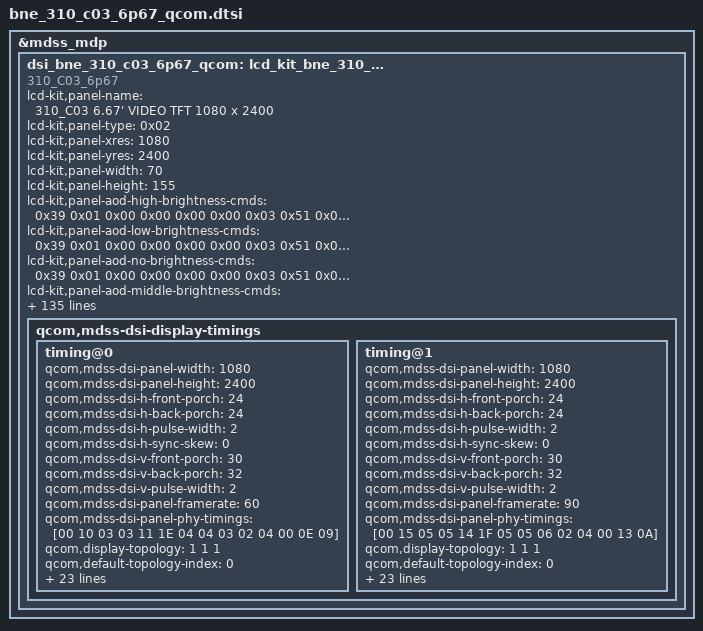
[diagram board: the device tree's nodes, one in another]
/* Copyright (c) 2013, The Linux Foundation. All rights reserved.
 *
 * This program is free software; you can redistribute it and/or modify
 * it under the terms of the GNU General Public License version 2 and
 * only version 2 as published by the Free Software Foundation.
 *
 * This program is distributed in the hope that it will be useful,
 * but WITHOUT ANY WARRANTY; without even the implied warranty of
 * MERCHANTABILITY or FITNESS FOR A PARTICULAR PURPOSE.  See the
 * GNU General Public License for more details.
 */

/*-------------------------------------------------------------------------
 * This file is autogenerated file using gcdb parser. Please do not edit it.
 * Update input XML file to add a new entry or update variable in this file
 * VERSION = 1.1
 *-----------------------------------------------------------------------*/
&mdss_mdp {
	dsi_bne_310_c03_6p67_qcom: lcd_kit_bne_310_c03_6p67_qcom {
		compatible = "310_C03_6p67";
		lcd-kit,panel-name = "310_C03 6.67' VIDEO TFT 1080 x 2400";
		lcd-kit,panel-type = <0x02>;
		lcd-kit,panel-xres = <1080>;
		lcd-kit,panel-yres = <2400>;
		lcd-kit,panel-width = <70>;
		lcd-kit,panel-height = <155>;
		lcd-kit,panel-aod-high-brightness-cmds = <0x39 0x01 0x00 0x00 0x00 0x00 0x03 0x51 0x0F 0xFF
		0x15 0x01 0x00 0x00 0x00 0x00 0x02 0xFE 0x00>;
		lcd-kit,panel-aod-low-brightness-cmds = <0x39 0x01 0x00 0x00 0x00 0x00 0x03 0x51 0x08 0x88
		0x15 0x01 0x00 0x00 0x00 0x00 0x02 0xFE 0x00>;
		lcd-kit,panel-aod-no-brightness-cmds = <0x39 0x01 0x00 0x00 0x00 0x00 0x03 0x51 0x00 0x00
		0x15 0x01 0x00 0x00 0x00 0x00 0x02 0xFE 0x00>;
		lcd-kit,panel-aod-middle-brightness-cmds = <0x39 0x01 0x00 0x00 0x00 0x00 0x03 0x51 0x0B 0xFF
		0x15 0x01 0x00 0x00 0x00 0x00 0x02 0xFE 0x00>;
		lcd-kit,hor-line-cmds = <0x15 0x01 0x00 0x00 0x0a 0x00 0x02 0xFE 0x84
		0x15 0x01 0x00 0x00 0x0a 0x00 0x02 0xE0 0x80
		0x15 0x01 0x00 0x00 0x0a 0x00 0x02 0xFE 0x40
		0x15 0x01 0x00 0x00 0x0a 0x00 0x02 0x74 0x4E
		0x15 0x01 0x00 0x00 0x0a 0x00 0x02 0x24 0x5F
		0x15 0x01 0x00 0x00 0x0a 0x00 0x02 0x26 0x5F
		0x15 0x01 0x00 0x00 0x0a 0x00 0x02 0x28 0x5F
		0x15 0x01 0x00 0x00 0x0a 0x00 0x02 0x2A 0x5F
		0x15 0x01 0x00 0x00 0x0a 0x00 0x02 0x2D 0x46
		0x15 0x01 0x00 0x00 0x0a 0x00 0x02 0x2F 0x46
		0x15 0x01 0x00 0x00 0x0a 0x00 0x02 0x36 0xC0
		0x15 0x01 0x00 0x00 0x0a 0x00 0x02 0x37 0x68
		0x15 0x01 0x00 0x00 0x0a 0x00 0x02 0x38 0x68
		0x15 0x01 0x00 0x00 0x00 0x00 0x02 0xFE 0x00>;
		lcd-kit,hor-line-cmds-state = "dsi_lp_mode";
		lcd-kit,vtc-line-cmds = <0x15 0x01 0x00 0x00 0x0a 0x00 0x02 0xFE 0x90
		0x15 0x01 0x00 0x00 0x0a 0x00 0x02 0x12 0xB7
		0x15 0x01 0x00 0x00 0x0a 0x00 0x02 0xFE 0x40
		0x15 0x01 0x00 0x00 0x0a 0x00 0x02 0x66 0xA0
		0x15 0x01 0x00 0x00 0x0a 0x00 0x02 0x67 0xC3
		0x15 0x01 0x00 0x00 0x0a 0x00 0x02 0xFE 0xA0
		0x15 0x01 0x00 0x00 0x0a 0x00 0x02 0x04 0x07
		0x15 0x01 0x00 0x00 0x0a 0x00 0x02 0x31 0x10
		0x15 0x01 0x00 0x00 0x0a 0x00 0x02 0x32 0x10
		0x15 0x01 0x00 0x00 0x0a 0x00 0x02 0xFE 0x40
		0x15 0x01 0x00 0x00 0x0a 0x00 0x02 0x74 0x4E
		0x15 0x01 0x00 0x00 0x0a 0x00 0x02 0xFE 0x70
		0x15 0x01 0x00 0x00 0x0a 0x00 0x02 0x71 0x00
		0x15 0x01 0x00 0x00 0x0a 0x00 0x02 0x72 0x31
		0x15 0x01 0x00 0x00 0x0a 0x00 0x02 0xFE 0x50
		0x15 0x01 0x00 0x00 0x0a 0x00 0x02 0x00 0xB9
		0x15 0x01 0x00 0x00 0x0a 0x00 0x02 0x01 0xB0
		0x15 0x01 0x00 0x00 0x0a 0x00 0x02 0x02 0x6F
		0x15 0x01 0x00 0x00 0x0a 0x00 0x02 0x03 0x90
		0x15 0x01 0x00 0x00 0x0a 0x00 0x02 0x04 0xEE
		0x15 0x01 0x00 0x00 0x00 0x00 0x02 0xFE 0x00>;
		lcd-kit,vtc-line-cmds-state  = "dsi_lp_mode";
		lcd-kit,bl-after-frame = <0>;
		lcd-kit,ap-aod-support = <1>;
		lcd-kit,dc-delay-support = <1>;
		lcd-kit,dc-left-time-to-te-us = <6800>;
		lcd-kit,dc-right-time-to-te-us = <7600>;
		lcd-kit,dc-delay-time-before-fp = <16667>;
		lcd-kit,dc-delay-time-after-fp = <16667>;
		lcd-kit,vtc-line-support = <0>;
		lcd-kit,hor-line-support = <0>;
		lcd-kit,hor-line-duration = <600>;
		lcd-kit,vtc-line-no-reset = <0>;
		qcom,mdss-dsi-panel-type = "dsi_cmd_mode";
		qcom,mdss-dsi-panel-name = "310_C03_6p67";
		qcom,mdss-pan-physical-width-dimension = <70>;
		qcom,mdss-pan-physical-height-dimension = <155>;
		qcom,dsi-ctrl-num = <0>;
		qcom,dsi-phy-num = <0>;
		qcom,panel-supply-entries = <&dsi_panel_pwr_supply>;
		qcom,mdss-dsi-virtual-channel-id = <0>;
		qcom,mdss-dsi-h-sync-pulse = <0>;
		qcom,mdss-dsi-bllp-eof-power-mode;
		qcom,mdss-dsi-bllp-power-mode;
		qcom,mdss-dsi-dma-schedule-line = <1>;
		qcom,mdss-dsi-bpp = <24>;
		qcom,mdss-dsi-color-order = "rgb_swap_rgb";
		qcom,mdss-dsi-underflow-color = <0xff>;
		qcom,mdss-dsi-border-color = <0>;
		qcom,mdss-dsi-traffic-mode = "burst_mode";
		qcom,mdss-dsi-lane-map = "lane_map_0123";
		qcom,mdss-dsi-lane-0-state;
		qcom,mdss-dsi-lane-1-state;
		qcom,mdss-dsi-lane-2-state;
		qcom,mdss-dsi-lane-3-state;
		qcom,mdss-dsi-mdp-trigger = "none";
		qcom,mdss-dsi-dma-trigger = "trigger_sw";
		qcom,mdss-dsi-te-pin-select = <1>;
		qcom,mdss-dsi-wr-mem-start = <0x2c>;
		qcom,mdss-dsi-wr-mem-continue = <0x3c>;
		qcom,mdss-dsi-te-dcs-command = <1>;
		qcom,mdss-dsi-te-check-enable;
		qcom,mdss-dsi-te-using-te-pin;
		qcom,dsi-panel-gpio-address = <0x0F100000 0x1000>;
		qcom,dsi-panel-gpio-pins = <12 82 81>;
		qcom,dsi-panel-gpio-names = "reg-gpio", "reset-gpio", "platform-te-gpio";
		qcom,mdss-dsi-t-clk-post = <0x09>;
		qcom,mdss-dsi-t-clk-pre = <0x0E>;
		qcom,mdss-dsi-tx-eot-append;
		qcom,dsi-select-clocks = "mux_byte_clk0", "mux_pixel_clk0", "src_byte_clk0", "src_pixel_clk0", "shadow_byte_clk0", "shadow_pixel_clk0";
		qcom,mdss-dsi-stream = <0>;
		qcom,mdss-dsi-lp11-init;
		qcom,sublinks-count = <2>;
		qcom,lanes-per-sublink = <2>;
		qcom,mdss-dsi-panel-hdr-color-primaries = <14500 15500 32000 17000 15500 30000 8000 3000>;
		qcom,mdss-dsi-panel-peak-brightness = <4200000>;
		qcom,mdss-dsi-panel-blackness-level = <3230>;
		qcom,dynamic-mode-switch-enabled;
		qcom,dynamic-mode-switch-type = "dynamic-resolution-switch-immediate";
		qcom,mdss-dsi-bl-pmic-control-type = "bl_ctrl_dcs";
		pwms = <&pm6125_pwm 0 0>;
		qcom,bl-pmic-pwm-period-usecs = <100>;
		qcom,mdss-dsi-bl-min-level = <1>;
		qcom,mdss-dsi-bl-max-level = <10000>;
		qcom,esd-check-enabled;
		qcom,mdss-dsi-panel-status-command = [15 01 00 00 00 00 02 FE 00
			06 01 00 00 00 00 01 0A
			15 01 00 00 00 00 02 FE D0
			15 01 00 00 11 00 02 B9 02
			15 01 00 00 00 00 02 B9 00
			15 01 00 00 11 00 02 FE 00
			15 01 00 00 00 00 02 FE 00
			06 01 00 00 00 00 01 FE];
		qcom,mdss-dsi-panel-status-command-state = "dsi_lp_mode";
		qcom,mdss-dsi-panel-status-check-mode = "reg_read";
		qcom,mdss-dsi-panel-status-read-length = <0 1 0 0 0 0 0 1>;
		qcom,mdss-dsi-panel-status-value = <0x9C>,<0x00>;
		lcd-kit,power-on-stage = <2 1 2
				9 1 1
				1 1 12
				5 1 5
				5 0 1
				5 1 15
				7 1 0
				6 1 0
				8 1 0>;
		lcd-kit,lp-on-stage = <0 0 0>;
		lcd-kit,lp-off-stage = <0 0 0>;
		lcd-kit,power-off-stage = <7 0 0
				6 0 0
				8 0 0
				5 0 1
				1 0 3
				9 0 2
				2 0 1>;
		lcd-kit,only-power-off-stage = <0 0 0>;
		lcd-kit,pt-support = <1>;
		lcd-kit,panel-on-always-reset = <0>;
		lcd-kit,lcd-vci = <2 27 3000000 3000000 3000000 10000 80>;
		lcd-kit,lcd-iovcc = <2 26 1800000 1800000 1800000 60700 80>;
		lcd-kit,lcd-vdd = <2 65 1200000 1200000 1200000 30000 80>;
		lcd-kit,lcd-reset = <2 82 0>;
		lcd-kit,lcd-vci-name = "vdd";
		lcd-kit,lcd-iovcc-name = "vddio";
		lcd-kit,lcd-vdd-name = "ddic";
		lcd-kit,project-id-support = <0>;
		lcd-kit,default-project-id = "G240A7130";
		lcd-kit,sn-code-support = <1>;
		lcd-kit,oem-info-support = <1>;
		lcd-kit,oem-barcode-2d-support = <1>;
		lcd-kit,oem-barcode-2d-num-offset = <0>;
		lcd-kit,barcode-2d-cmds = <0x15 0x01 0x00 0x00 0x00 0x00 0x02 0xFE 0xC2
		0x06 0x01 0x00 0x00 0x00 0x00 0x01 0x01
		0x06 0x01 0x00 0x00 0x00 0x00 0x01 0x02
		0x06 0x01 0x00 0x00 0x00 0x00 0x01 0x03
		0x06 0x01 0x00 0x00 0x00 0x00 0x01 0x04
		0x06 0x01 0x00 0x00 0x00 0x00 0x01 0x05
		0x06 0x01 0x00 0x00 0x00 0x00 0x01 0x06
		0x06 0x01 0x00 0x00 0x00 0x00 0x01 0x07
		0x06 0x01 0x00 0x00 0x00 0x00 0x01 0x08
		0x06 0x01 0x00 0x00 0x00 0x00 0x01 0x09
		0x06 0x01 0x00 0x00 0x00 0x00 0x01 0x0A
		0x06 0x01 0x00 0x00 0x00 0x00 0x01 0x0B
		0x06 0x01 0x00 0x00 0x00 0x00 0x01 0x0C
		0x06 0x01 0x00 0x00 0x00 0x00 0x01 0x0D
		0x06 0x01 0x00 0x00 0x00 0x00 0x01 0x0E
		0x06 0x01 0x00 0x00 0x00 0x00 0x01 0x0F
		0x06 0x01 0x00 0x00 0x00 0x00 0x01 0x10
		0x06 0x01 0x00 0x00 0x00 0x00 0x01 0x11
		0x06 0x01 0x00 0x00 0x00 0x00 0x01 0x12
		0x06 0x01 0x00 0x00 0x00 0x00 0x01 0x13
		0x06 0x01 0x00 0x00 0x00 0x00 0x01 0x14
		0x06 0x01 0x00 0x00 0x00 0x00 0x01 0x15
		0x15 0x01 0x00 0x00 0x00 0x00 0x02 0xFE 0x00>;
		lcd-kit,barcode-2d-cmds-state = "dsi_lp_mode";
		lcd-kit,panel-getblmaxnit-type = <0>;
		lcd-kit,panel-blmaxnit-min-value = <400>;
		lcd-kit,inversion-support = <0>;
		lcd-kit,panel-gpio-offset = <1167>;
		lcd-kit,panel-bl-max-nit = <450>;
		lcd-kit,panel-bl-min = <1>;
		lcd-kit,panel-bl-max = <10000>;
		lcd-kit,panel-bl-def = <2047>;
		lcd-kit,check-reg-support = <0>;
		lcd-kit,thp-proximity-support = <0>;
		lcd-kit,proximity-reset-delay-min = <65>;
		lcd-kit,backlight-cmds = <0x39 0x01 0x00 0x00 0x00 0x00 0x03 0x51 0x00 0x00>;
		lcd-kit,backlight-cmds-state = "dsi_lp_mode";
		lcd-kit,backlight-order = <0>;
		lcd-kit,quickly-sleep-out-support = <0>;
		lcd-kit,quickly-sleep-out-interval = <0>;
		lcd-kit,fps-support = <1>;
		lcd-kit,default-fps = <60>;
		lcd-kit,panel-support-fps-list = <60 90>;
		qcom,mdss-dsi-display-timings {
			timing@0 {
				qcom,mdss-dsi-panel-width = <1080>;
				qcom,mdss-dsi-panel-height = <2400>;
				qcom,mdss-dsi-h-front-porch = <24>;
				qcom,mdss-dsi-h-back-porch = <24>;
				qcom,mdss-dsi-h-pulse-width = <2>;
				qcom,mdss-dsi-h-sync-skew = <0>;
				qcom,mdss-dsi-v-front-porch = <30>;
				qcom,mdss-dsi-v-back-porch = <32>;
				qcom,mdss-dsi-v-pulse-width = <2>;
				qcom,mdss-dsi-panel-framerate = <60>;
				qcom,mdss-dsi-panel-phy-timings= [00 10 03 03 11 1E 04
			04 03 02 04 00 0E 09];
				qcom,display-topology  = <1 1 1>;
				qcom,default-topology-index  = <0>;
				qcom,mdss-dsi-on-command = [15 01 00 00 00 00 02 FE D0
		15 01 00 00 00 00 02 2A 80
		15 01 00 00 00 00 02 FE D2
		15 01 00 00 00 00 02 53 08
		15 01 00 00 00 00 02 00 11
		15 01 00 00 00 00 02 01 AB
		15 01 00 00 00 00 02 02 30
		15 01 00 00 00 00 02 03 09
		15 01 00 00 00 00 02 04 60
		15 01 00 00 00 00 02 05 04
		15 01 00 00 00 00 02 06 38
		15 01 00 00 00 00 02 07 00
		15 01 00 00 00 00 02 08 0C
		15 01 00 00 00 00 02 09 04
		15 01 00 00 00 00 02 0A 38
		15 01 00 00 00 00 02 0B 02
		15 01 00 00 00 00 02 0C 00
		15 01 00 00 00 00 02 0D 20
		15 01 00 00 00 00 02 0E 01
		15 01 00 00 00 00 02 0F 47
		15 01 00 00 00 00 02 10 00
		15 01 00 00 00 00 02 11 0F
		15 01 00 00 00 00 02 12 0F
		15 01 00 00 00 00 02 13 0A
		15 01 00 00 00 00 02 14 E9
		15 01 00 00 00 00 02 15 04
		15 01 00 00 00 00 02 16 3D
		15 01 00 00 00 00 02 17 18
		15 01 00 00 00 00 02 18 00
		15 01 00 00 00 00 02 19 10
		15 01 00 00 00 00 02 1A F0
		15 01 00 00 00 00 02 1B 07
		15 01 00 00 00 00 02 1C 10
		15 01 00 00 00 00 02 1D 20
		15 01 00 00 00 00 02 1E 00
		15 01 00 00 00 00 02 1F 06
		15 01 00 00 00 00 02 20 0F
		15 01 00 00 00 00 02 21 0F
		15 01 00 00 00 00 02 22 33
		15 01 00 00 00 00 02 23 0E
		15 01 00 00 00 00 02 24 1C
		15 01 00 00 00 00 02 25 2A
		15 01 00 00 00 00 02 26 38
		15 01 00 00 00 00 02 27 46
		15 01 00 00 00 00 02 28 54
		15 01 00 00 00 00 02 29 62
		15 01 00 00 00 00 02 2A 69
		15 01 00 00 00 00 02 2B 70
		15 01 00 00 00 00 02 2D 77
		15 01 00 00 00 00 02 2F 79
		15 01 00 00 00 00 02 30 7B
		15 01 00 00 00 00 02 31 7D
		15 01 00 00 00 00 02 32 7E
		15 01 00 00 00 00 02 33 02
		15 01 00 00 00 00 02 34 02
		15 01 00 00 00 00 02 35 22
		15 01 00 00 00 00 02 36 00
		15 01 00 00 00 00 02 37 2A
		15 01 00 00 00 00 02 38 40
		15 01 00 00 00 00 02 39 2A
		15 01 00 00 00 00 02 3A BE
		15 01 00 00 00 00 02 3B 3A
		15 01 00 00 00 00 02 3D FC
		15 01 00 00 00 00 02 3F 3A
		15 01 00 00 00 00 02 40 FA
		15 01 00 00 00 00 02 41 3A
		15 01 00 00 00 00 02 42 F8
		15 01 00 00 00 00 02 43 3B
		15 01 00 00 00 00 02 44 38
		15 01 00 00 00 00 02 45 3B
		15 01 00 00 00 00 02 46 78
		15 01 00 00 00 00 02 47 3B
		15 01 00 00 00 00 02 48 B6
		15 01 00 00 00 00 02 49 4B
		15 01 00 00 00 00 02 4A B6
		15 01 00 00 00 00 02 4B 4B
		15 01 00 00 00 00 02 4C F4
		15 01 00 00 00 00 02 4D 4B
		15 01 00 00 00 00 02 4E F4
		15 01 00 00 00 00 02 4F 6C
		15 01 00 00 00 00 02 50 34
		15 01 00 00 00 00 02 51 84
		15 01 00 00 00 00 02 52 74
		15 01 00 00 00 00 02 86 04
		15 01 00 00 00 00 02 87 38
		15 01 00 00 00 00 02 88 00
		15 01 00 00 00 00 02 89 00
		15 01 00 00 00 00 02 8A 00
		15 01 00 00 00 00 02 8B 00
		15 01 00 00 00 00 02 8C 00
		15 01 00 00 00 00 02 8D 00
		15 01 00 00 00 00 02 8E 80
		15 01 00 00 00 00 02 FE A0
		15 01 00 00 00 00 02 28 1B
		15 01 00 00 00 00 02 FE 40
		15 01 00 00 00 00 02 2F 25
		15 01 00 00 00 00 02 47 2F
		15 01 00 00 00 00 02 FE 70
		15 01 00 00 00 00 02 19 2E
		15 01 00 00 00 00 02 FE 84
		15 01 00 00 00 00 02 E0 90
		15 01 00 00 00 00 02 D9 80
		15 01 00 00 00 00 02 E1 BC
		15 01 00 00 00 00 02 E7 04
		15 01 00 00 00 00 02 E8 D0
		15 01 00 00 00 00 02 FE D0
		15 01 00 00 00 00 02 9C 84
		15 01 00 00 00 00 02 48 D0
		15 01 00 00 00 00 02 FE 78
		15 01 00 00 00 00 02 A0 01
		15 01 00 00 00 00 02 A2 01
		15 01 00 00 00 00 02 A3 02
		15 01 00 00 00 00 02 A4 04
		15 01 00 00 00 00 02 A5 05
		15 01 00 00 00 00 02 A6 06
		15 01 00 00 00 00 02 A7 07
		15 01 00 00 00 00 02 A9 08
		15 01 00 00 00 00 02 AA 09
		15 01 00 00 00 00 02 AB 09
		15 01 00 00 00 00 02 AC 0A
		15 01 00 00 00 00 02 FE 84
		15 01 00 00 00 00 02 59 0B
		15 01 00 00 00 00 02 5A 0B
		15 01 00 00 00 00 02 5B 0C
		15 01 00 00 00 00 02 5C 0E
		15 01 00 00 00 00 02 5D 0F
		15 01 00 00 00 00 02 5E 10
		15 01 00 00 00 00 02 5F 11
		15 01 00 00 00 00 02 60 12
		15 01 00 00 00 00 02 61 13
		15 01 00 00 00 00 02 62 13
		15 01 00 00 00 00 02 63 14
		15 01 00 00 00 00 02 FE 82
		15 01 00 00 00 00 02 00 01
		15 01 00 00 00 00 02 02 D0
		15 01 00 00 00 00 02 03 0A
		15 01 00 00 00 00 02 05 F0
		15 01 00 00 00 00 02 A4 DD
		15 01 00 00 00 00 02 A5 DD
		15 01 00 00 00 00 02 A6 DD
		15 01 00 00 00 00 02 A7 DD
		15 01 00 00 00 00 02 A9 DD
		15 01 00 00 00 00 02 AA DD
		15 01 00 00 00 00 02 AB DD
		15 01 00 00 00 00 02 AC DD
		15 01 00 00 00 00 02 AD FF
		15 01 00 00 00 00 02 AE FF
		15 01 00 00 00 00 02 AF FF
		15 01 00 00 00 00 02 B0 FF
		15 01 00 00 00 00 02 8B FF
		15 01 00 00 00 00 02 8C FF
		15 01 00 00 00 00 02 9A FF
		15 01 00 00 00 00 02 9B FF
		15 01 00 00 00 00 02 FE A0
		15 01 00 00 00 00 02 1F 1E
		15 01 00 00 00 00 02 30 37
		15 01 00 00 00 00 02 FE D0
		15 01 00 00 00 00 02 42 81
		15 01 00 00 00 00 02 FE 00
		15 01 00 00 00 00 02 FA 01
		15 01 00 00 00 00 02 5E 01
		15 01 00 00 00 00 02 C2 08
		15 01 00 00 00 00 02 35 00
		05 01 00 00 78 00 01 11
		05 01 00 00 14 00 01 29
		15 01 00 00 00 00 02 FE 00];
				qcom,mdss-dsi-on-command-state = "dsi_lp_mode";
				qcom,mdss-dsi-off-command = [05 01 00 00 14 00 01 28
		05 01 00 00 78 00 01 10
		15 01 00 00 00 00 02 FE 00];
				qcom,mdss-dsi-off-command-state = "dsi_lp_mode";
				qcom,compression-mode = "dsc";
				qcom,mdss-dsc-slice-height = <12>;
				qcom,mdss-dsc-slice-width = <1080>;
				qcom,mdss-dsc-slice-per-pkt = <1>;
				qcom,mdss-dsc-bit-per-component = <10>;
				qcom,mdss-dsc-bit-per-pixel = <8>;
				qcom,mdss-dsc-block-prediction-enable;
				qcom,mdss-dsi-timing-switch-command = [15 01 00 00 00 00 02 FE 84
		15 01 00 00 00 00 02 E0 90
		15 01 00 00 16 00 02 FE 00];
				qcom,mdss-dsi-timing-switch-command-state = "dsi_lp_mode";
				qcom,mdss-dsi-lp1-command = [15 01 00 00 00 00 02 FE 84
		15 01 00 00 00 00 02 E0 90
		15 01 00 00 00 00 02 FE 00
		05 01 00 00 00 00 01 39];
				qcom,mdss-dsi-lp1-command-state = "dsi_lp_mode";
				qcom,mdss-dsi-nolp-command = [15 01 00 00 00 00 02 FE 84
		15 01 00 00 00 00 02 E0 90
		15 01 00 00 00 00 02 FE 00
		39 01 00 00 00 00 03 51 00 00
		05 01 00 00 00 00 01 38];
				qcom,mdss-dsi-nolp-command-state = "dsi_lp_mode";
			};
			timing@1 {
				qcom,mdss-dsi-panel-width = <1080>;
				qcom,mdss-dsi-panel-height = <2400>;
				qcom,mdss-dsi-h-front-porch = <24>;
				qcom,mdss-dsi-h-back-porch = <24>;
				qcom,mdss-dsi-h-pulse-width = <2>;
				qcom,mdss-dsi-h-sync-skew = <0>;
				qcom,mdss-dsi-v-front-porch = <30>;
				qcom,mdss-dsi-v-back-porch = <32>;
				qcom,mdss-dsi-v-pulse-width = <2>;
				qcom,mdss-dsi-panel-framerate = <90>;
				qcom,mdss-dsi-panel-phy-timings= [00 15 05 05 14 1F 05
			05 06 02 04 00 13 0A];
				qcom,display-topology  = <1 1 1>;
				qcom,default-topology-index  = <0>;
				qcom,mdss-dsi-on-command = [15 01 00 00 00 00 02 FE D0
		15 01 00 00 00 00 02 2A 80
		15 01 00 00 00 00 02 FE D2
		15 01 00 00 00 00 02 53 08
		15 01 00 00 00 00 02 00 11
		15 01 00 00 00 00 02 01 AB
		15 01 00 00 00 00 02 02 30
		15 01 00 00 00 00 02 03 09
		15 01 00 00 00 00 02 04 60
		15 01 00 00 00 00 02 05 04
		15 01 00 00 00 00 02 06 38
		15 01 00 00 00 00 02 07 00
		15 01 00 00 00 00 02 08 0C
		15 01 00 00 00 00 02 09 04
		15 01 00 00 00 00 02 0A 38
		15 01 00 00 00 00 02 0B 02
		15 01 00 00 00 00 02 0C 00
		15 01 00 00 00 00 02 0D 20
		15 01 00 00 00 00 02 0E 01
		15 01 00 00 00 00 02 0F 47
		15 01 00 00 00 00 02 10 00
		15 01 00 00 00 00 02 11 0F
		15 01 00 00 00 00 02 12 0F
		15 01 00 00 00 00 02 13 0A
		15 01 00 00 00 00 02 14 E9
		15 01 00 00 00 00 02 15 04
		15 01 00 00 00 00 02 16 3D
		15 01 00 00 00 00 02 17 18
		15 01 00 00 00 00 02 18 00
		15 01 00 00 00 00 02 19 10
		15 01 00 00 00 00 02 1A F0
		15 01 00 00 00 00 02 1B 07
		15 01 00 00 00 00 02 1C 10
		15 01 00 00 00 00 02 1D 20
		15 01 00 00 00 00 02 1E 00
		15 01 00 00 00 00 02 1F 06
		15 01 00 00 00 00 02 20 0F
		15 01 00 00 00 00 02 21 0F
		15 01 00 00 00 00 02 22 33
		15 01 00 00 00 00 02 23 0E
		15 01 00 00 00 00 02 24 1C
		15 01 00 00 00 00 02 25 2A
		15 01 00 00 00 00 02 26 38
		15 01 00 00 00 00 02 27 46
		15 01 00 00 00 00 02 28 54
		15 01 00 00 00 00 02 29 62
		15 01 00 00 00 00 02 2A 69
		15 01 00 00 00 00 02 2B 70
		15 01 00 00 00 00 02 2D 77
		15 01 00 00 00 00 02 2F 79
		15 01 00 00 00 00 02 30 7B
		15 01 00 00 00 00 02 31 7D
		15 01 00 00 00 00 02 32 7E
		15 01 00 00 00 00 02 33 02
		15 01 00 00 00 00 02 34 02
		15 01 00 00 00 00 02 35 22
		15 01 00 00 00 00 02 36 00
		15 01 00 00 00 00 02 37 2A
		15 01 00 00 00 00 02 38 40
		15 01 00 00 00 00 02 39 2A
		15 01 00 00 00 00 02 3A BE
		15 01 00 00 00 00 02 3B 3A
		15 01 00 00 00 00 02 3D FC
		15 01 00 00 00 00 02 3F 3A
		15 01 00 00 00 00 02 40 FA
		15 01 00 00 00 00 02 41 3A
		15 01 00 00 00 00 02 42 F8
		15 01 00 00 00 00 02 43 3B
		15 01 00 00 00 00 02 44 38
		15 01 00 00 00 00 02 45 3B
		15 01 00 00 00 00 02 46 78
		15 01 00 00 00 00 02 47 3B
		15 01 00 00 00 00 02 48 B6
		15 01 00 00 00 00 02 49 4B
		15 01 00 00 00 00 02 4A B6
		15 01 00 00 00 00 02 4B 4B
		15 01 00 00 00 00 02 4C F4
		15 01 00 00 00 00 02 4D 4B
		15 01 00 00 00 00 02 4E F4
		15 01 00 00 00 00 02 4F 6C
		15 01 00 00 00 00 02 50 34
		15 01 00 00 00 00 02 51 84
		15 01 00 00 00 00 02 52 74
		15 01 00 00 00 00 02 86 04
		15 01 00 00 00 00 02 87 38
		15 01 00 00 00 00 02 88 00
		15 01 00 00 00 00 02 89 00
		15 01 00 00 00 00 02 8A 00
		15 01 00 00 00 00 02 8B 00
		15 01 00 00 00 00 02 8C 00
		15 01 00 00 00 00 02 8D 00
		15 01 00 00 00 00 02 8E 80
		15 01 00 00 00 00 02 FE A0
		15 01 00 00 00 00 02 28 1B
		15 01 00 00 00 00 02 FE 40
		15 01 00 00 00 00 02 2F 25
		15 01 00 00 00 00 02 47 2F
		15 01 00 00 00 00 02 FE 70
		15 01 00 00 00 00 02 19 2E
		15 01 00 00 00 00 02 FE 84
		15 01 00 00 00 00 02 E0 80
		15 01 00 00 00 00 02 D9 80
		15 01 00 00 00 00 02 E1 BC
		15 01 00 00 00 00 02 E7 04
		15 01 00 00 00 00 02 E8 D0
		15 01 00 00 00 00 02 FE D0
		15 01 00 00 00 00 02 9C 84
		15 01 00 00 00 00 02 48 D0
		15 01 00 00 00 00 02 FE 78
		15 01 00 00 00 00 02 A0 01
		15 01 00 00 00 00 02 A2 01
		15 01 00 00 00 00 02 A3 02
		15 01 00 00 00 00 02 A4 04
		15 01 00 00 00 00 02 A5 05
		15 01 00 00 00 00 02 A6 06
		15 01 00 00 00 00 02 A7 07
		15 01 00 00 00 00 02 A9 08
		15 01 00 00 00 00 02 AA 09
		15 01 00 00 00 00 02 AB 09
		15 01 00 00 00 00 02 AC 0A
		15 01 00 00 00 00 02 FE 84
		15 01 00 00 00 00 02 59 0B
		15 01 00 00 00 00 02 5A 0B
		15 01 00 00 00 00 02 5B 0C
		15 01 00 00 00 00 02 5C 0E
		15 01 00 00 00 00 02 5D 0F
		15 01 00 00 00 00 02 5E 10
		15 01 00 00 00 00 02 5F 11
		15 01 00 00 00 00 02 60 12
		15 01 00 00 00 00 02 61 13
		15 01 00 00 00 00 02 62 13
		15 01 00 00 00 00 02 63 14
		15 01 00 00 00 00 02 FE 82
		15 01 00 00 00 00 02 00 01
		15 01 00 00 00 00 02 02 D0
		15 01 00 00 00 00 02 03 0A
		15 01 00 00 00 00 02 05 F0
		15 01 00 00 00 00 02 A4 DD
		15 01 00 00 00 00 02 A5 DD
		15 01 00 00 00 00 02 A6 DD
		15 01 00 00 00 00 02 A7 DD
		15 01 00 00 00 00 02 A9 DD
		15 01 00 00 00 00 02 AA DD
		15 01 00 00 00 00 02 AB DD
		15 01 00 00 00 00 02 AC DD
		15 01 00 00 00 00 02 AD FF
		15 01 00 00 00 00 02 AE FF
		15 01 00 00 00 00 02 AF FF
		15 01 00 00 00 00 02 B0 FF
		15 01 00 00 00 00 02 8B FF
		15 01 00 00 00 00 02 8C FF
		15 01 00 00 00 00 02 9A FF
		15 01 00 00 00 00 02 9B FF
		15 01 00 00 00 00 02 FE A0
		15 01 00 00 00 00 02 1F 1E
		15 01 00 00 00 00 02 30 37
		15 01 00 00 00 00 02 FE D0
		15 01 00 00 00 00 02 42 81
		15 01 00 00 00 00 02 FE 00
		15 01 00 00 00 00 02 FA 01
		15 01 00 00 00 00 02 5E 01
		15 01 00 00 00 00 02 C2 08
		15 01 00 00 00 00 02 35 00
		05 01 00 00 78 00 01 11
		05 01 00 00 14 00 01 29
		15 01 00 00 00 00 02 FE 00];
				qcom,mdss-dsi-on-command-state = "dsi_lp_mode";
				qcom,mdss-dsi-off-command = [05 01 00 00 14 00 01 28
		05 01 00 00 78 00 01 10
		15 01 00 00 00 00 02 FE 00];
				qcom,mdss-dsi-off-command-state = "dsi_lp_mode";
				qcom,compression-mode = "dsc";
				qcom,mdss-dsc-slice-height = <12>;
				qcom,mdss-dsc-slice-width = <1080>;
				qcom,mdss-dsc-slice-per-pkt = <1>;
				qcom,mdss-dsc-bit-per-component = <10>;
				qcom,mdss-dsc-bit-per-pixel = <8>;
				qcom,mdss-dsc-block-prediction-enable;
				qcom,mdss-dsi-timing-switch-command = [15 01 00 00 00 00 02 FE 84
		15 01 00 00 00 00 02 E0 80
		15 01 00 00 00 00 02 FE 00];
				qcom,mdss-dsi-timing-switch-command-state = "dsi_lp_mode";
				qcom,mdss-dsi-lp1-command = [15 01 00 00 00 00 02 FE 84
		15 01 00 00 00 00 02 E0 90
		15 01 00 00 00 00 02 FE 00
		05 01 00 00 00 00 01 39];
				qcom,mdss-dsi-lp1-command-state = "dsi_lp_mode";
				qcom,mdss-dsi-nolp-command = [15 01 00 00 00 00 02 FE 84
		15 01 00 00 00 00 02 E0 80
		15 01 00 00 00 00 02 FE 00
		39 01 00 00 00 00 03 51 00 00
		05 01 00 00 00 00 01 38];
				qcom,mdss-dsi-nolp-command-state = "dsi_lp_mode";
			};
		};
    };
};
